# fcr_me21 register map
Registers are read-write, no defined reset value unless marked. A register's access mark holds for its fields unless they carry their own. Offsets are from the block's base; lines under a group give offsets from that group; [hi:lo] are bit positions; {n}, {i} and the like mark numbered series; 'fields as' and 'values as' point back to an identical list; <NAME> marks a mode.

## Memory map
0x40000800 FCR size 0x400 — Function Control Register.

## FCR — Function Control Register.
Base 0x40000800
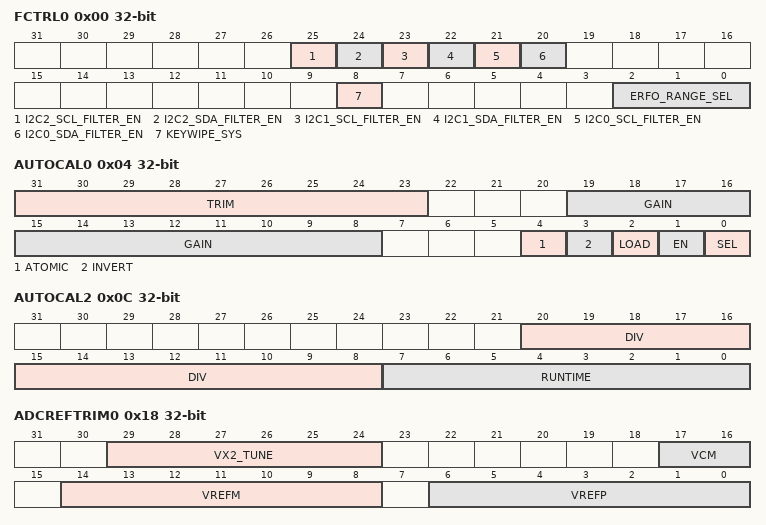
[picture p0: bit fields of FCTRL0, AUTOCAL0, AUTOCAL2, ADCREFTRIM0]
0x00 FCTRL0 — Register 0.
  [25] I2C2_SCL_FILTER_EN — I2C2 SCL Glitch Filter Enable.
    0=dis (Filter disabled.); 1=en (Filter enabled.)
  [24] I2C2_SDA_FILTER_EN — I2C2 SDA Glitch Filter Enable.
    0=dis (Filter disabled.); 1=en (Filter enabled.)
  [23] I2C1_SCL_FILTER_EN — I2C1 SCL Glitch Filter Enable.
    0=dis (Filter disabled.); 1=en (Filter enabled.)
  [22] I2C1_SDA_FILTER_EN — I2C1 SDA Glitch Filter Enable.
    0=dis (Filter disabled.); 1=en (Filter enabled.)
  [21] I2C0_SCL_FILTER_EN — I2C0 SCL Glitch Filter Enable.
    0=dis (Filter disabled.); 1=en (Filter enabled.)
  [20] I2C0_SDA_FILTER_EN — I2C0 SDA Glitch Filter Enable.
    0=dis (Filter disabled.); 1=en (Filter enabled.)
  [8] KEYWIPE_SYS
  [2:0] ERFO_RANGE_SEL — 14MHz-32MHz ERFO Frequency Range Select.
0x04 AUTOCAL0 — Register 1.
  [31:23] TRIM — 150MHz HFIO Auto Calibration Trim
  [19:8] GAIN — MU value.
  [4] ATOMIC — Atomic mode.
    0=not (Not Running.); 1=run (Running.)
  [3] INVERT — Invert Gain.
    0=not (do Not invert trim step.); 1=Invert trim step
  [2] LOAD — Load Trim.
  [1] EN — Autocalibration Run.
    0=not (Not Running.); 1=run (Running.)
  [0] SEL — Auto-calibration Enable.
    0=dis (Disabled.); 1=en (Enabled.)
0x08 AUTOCAL1 — Register 2.
  [8:0] INITIAL — 100MHz IPO Trim Automatic Calibration Initial Trim.
0x0C AUTOCAL2 — Register 3.
  [20:8] DIV — 100MHz IPO Trim Automatic Calibration Divide Factor.
  [7:0] RUNTIME — 100MHz IPO Trim Automatic Calibration Run Time.
0x10 TS0 ro — Register 4.
  [11:0] GAIN — Unsigned gain for temp sensor normalization
0x14 TS1 ro — Register 5.
  [31:0] OFFSET — Signed offset for temp sensor correction
0x18 ADCREFTRIM0 — ADC Reference Trim 0
  [29:24] VX2_TUNE — Controls tuning capacitor in fine DAC (offset binary)
  [17:16] VCM — Trimming code for VCM output of reference buffer
  [14:8] VREFM — Trimming code for VREFM output of reference buffer
  [6:0] VREFP — Trimming code for VREFP output of reference buffer
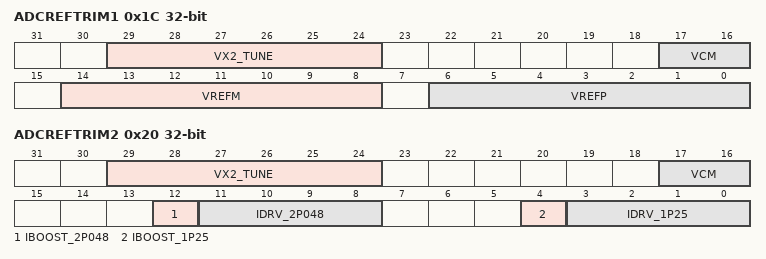
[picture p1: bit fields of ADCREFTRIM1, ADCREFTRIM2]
0x1C ADCREFTRIM1 — ADC Reference Trim 1
  fields as ADCREFTRIM0
0x20 ADCREFTRIM2 — ADC Reference Trim 2
  [29:24] VX2_TUNE — Controls tuning capacitor in fine DAC (offset binary)
  [17:16] VCM — Trimming code for VCM output of reference buffer
  [12] IBOOST_2P048 — Trimming value for extra drive current in reference buffer outputs. 2.048V
  [11:8] IDRV_2P048 — Trimming code for reference buffer drive strength. 2.048V
  [4] IBOOST_1P25 — Trimming value for extra drive current in reference buffer outputs. 2.048V
  [3:0] IDRV_1P25 — Trimming code for reference buffer drive strength. 1.25V
0x24 ERFOKS — External Radio Frequency Oscillator Kick Start Control Register.
  [15:0] CTRL — Kickstart Control for ERFO.
